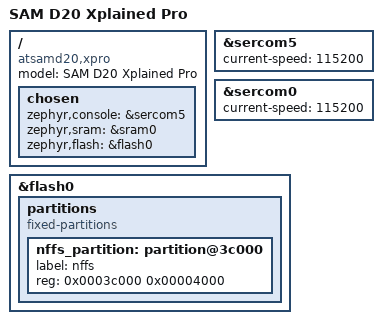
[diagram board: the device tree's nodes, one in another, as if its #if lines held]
/*
 * Copyright (c) 2018 Sean Nyekjaer
 *
 * SPDX-License-Identifier: Apache-2.0
 */

/dts-v1/;
#include <atmel/samd20.dtsi>

/ {
	model = "SAM D20 Xplained Pro";
	compatible = "atsamd20,xpro", "atmel,samd20j18", "atmel,samd20";

	chosen {
		zephyr,console = &sercom5;
		zephyr,sram = &sram0;
		zephyr,flash = &flash0;
	};
};

&sercom5 {
	status = "ok";
	current-speed = <115200>;
};
&sercom0 {
	status = "ok";
	current-speed = <115200>;
};

&flash0 {
	partitions {
		compatible = "fixed-partitions";
		#address-cells = <1>;
		#size-cells = <1>;

		/*
		 * The final 16 KiB is reserved for the application
		 * and is used by NFFS if enabled.
		 */

#if defined(CONFIG_FILE_SYSTEM_NFFS)
		nffs_partition: partition@3c000 {
			label = "nffs";
			reg = <0x0003c000 0x00004000>;
		};
#endif
	};
};
